# STM32H757xx register map
File version: 1.0
Registers are 32-bit, access not given, reset 0x0 unless marked. A register's access mark holds for its fields unless they carry their own. Offsets are from the block's base; [hi:lo] are bit positions; {n}, {i} and the like mark numbered series; 'fields as' and 'values as' point back to an identical list.

## DLYB_SDMMC2
Base 0x48022800
Same registers: DLYB_QUADSPI 0x52006000, DLYB_SDMMC1 0x52008000
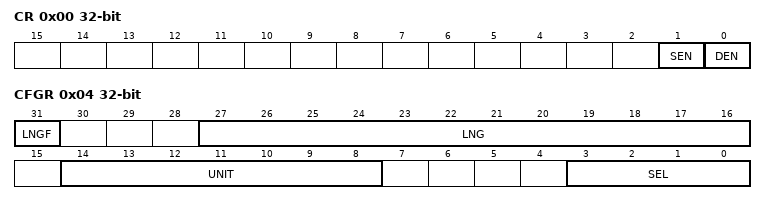
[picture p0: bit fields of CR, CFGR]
0x00 CR
  [1] SEN, [0] DEN
0x04 CFGR
  [31] LNGF, [27:16] LNG, [14:8] UNIT, [3:0] SEL

## RAMECC2
Base 0x48023000
Same registers: RAMECC1 0x52009000, RAMECC3 0x58027000
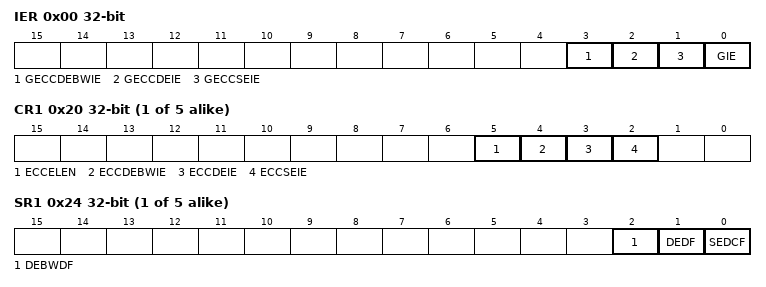
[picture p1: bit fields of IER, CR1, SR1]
0x00 IER
  [3] GECCDEBWIE, [2] GECCDEIE, [1] GECCSEIE, [0] GIE
{0x0+0x20*i} CR{i} (i=1..5)
  [5] ECCELEN, [4] ECCDEBWIE, [3] ECCDEIE, [2] ECCSEIE
{0x4+0x20*i} SR{i} (i=1..5)
  [2] DEBWDF, [1] DEDF, [0] SEDCF
{0xC+0x20*i} FAR{i} (i=1..5)
  [31:0] FDATAL
{0x18+0x20*i} FDRL{i} (i=1..5)
{0x28+0x20*i} FDRH{i} (i=1..5)
{0x3C+0x20*i} FECR{i} (i=1..5)
  [31:0] FEC

## LTDC
Base 0x50001000
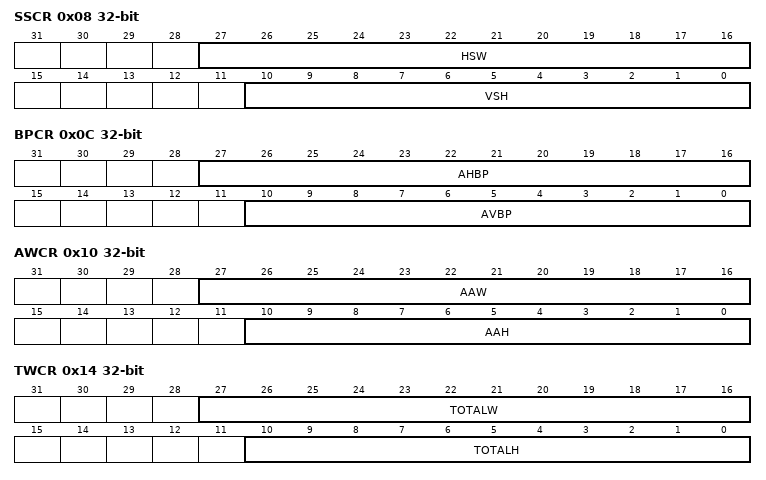
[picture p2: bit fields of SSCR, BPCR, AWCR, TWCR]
0x08 SSCR
  [27:16] HSW, [10:0] VSH
0x0C BPCR
  [27:16] AHBP, [10:0] AVBP
0x10 AWCR
  [27:16] AAW, [10:0] AAH
0x14 TWCR
  [27:16] TOTALW, [10:0] TOTALH
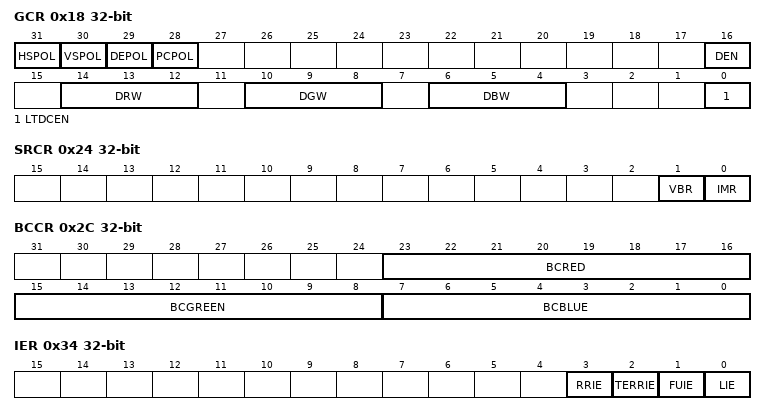
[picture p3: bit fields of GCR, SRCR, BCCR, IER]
0x18 GCR
  [31] HSPOL, [30] VSPOL, [29] DEPOL, [28] PCPOL, [16] DEN, [14:12] DRW, [10:8] DGW, [6:4] DBW, [0] LTDCEN
0x24 SRCR
  [1] VBR, [0] IMR
0x2C BCCR
  [23:16] BCRED, [15:8] BCGREEN, [7:0] BCBLUE
0x34 IER
  [3] RRIE, [2] TERRIE, [1] FUIE, [0] LIE
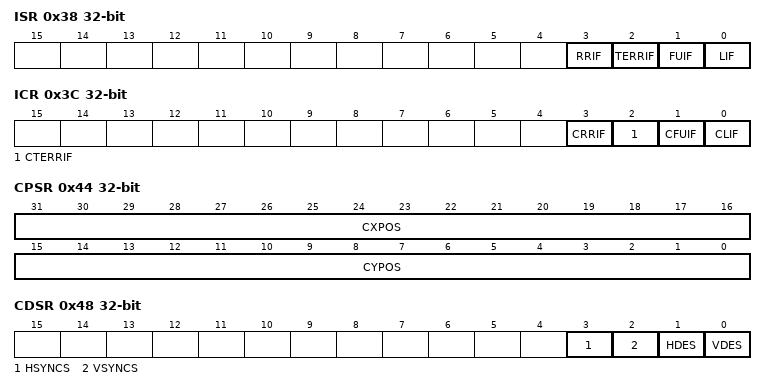
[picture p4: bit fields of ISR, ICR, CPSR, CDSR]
0x38 ISR
  [3] RRIF, [2] TERRIF, [1] FUIF, [0] LIF
0x3C ICR
  [3] CRRIF, [2] CTERRIF, [1] CFUIF, [0] CLIF
0x40 LIPCR
  [10:0] LIPOS
0x44 CPSR
  [31:16] CXPOS, [15:0] CYPOS
0x48 CDSR
  [3] HSYNCS, [2] VSYNCS, [1] HDES, [0] VDES
0x84 CR1
0x88 WHPCR1
0x90 WVPCR1
0x9C CKCR1
0xAC PFCR1
0xC0 CACR1
0xD8 DCCR1
0xF4 BFCR1
0x104 CR2
0x108 WHPCR2
0x110 WVPCR2
0x11C CFBAR1
0x11C CKCR2
0x12C PFCR2
0x140 CACR2
0x148 CFBLR1
0x158 DCCR2
0x174 BFCR2
0x178 CFBLNR1
0x19C CFBAR2
0x1B8 CLUTWR1
0x1C8 CFBLR2
0x1F8 CFBLNR2
0x238 CLUTWR2

## GPV
Base 0x51000000
{0x1FC0+4i} AXI_PERIPH_ID_{i} (i=4..7)
{0x1FE0+4i} AXI_PERIPH_ID_{i} (i=0..3)
{0x1FF0+4i} AXI_COMP_ID_{i} (i=0..3)
{0x1008+0x1000*i} AXI_TARG{i}_FN_MOD_ISS_BM (i=1..7)
0x2024 AXI_TARG1_FN_MOD2
0x202C AXI_TARG1_FN_MOD_LB
0x2108 AXI_TARG1_FN_MOD
0x3024 AXI_TARG2_FN_MOD2
0x302C AXI_TARG2_FN_MOD_LB
0x3108 AXI_TARG2_FN_MOD
0x8024 AXI_TARG7_FN_MOD2
0x802C AXI_TARG7_FN_MOD_LB
0x8108 AXI_TARG7_FN_MOD
0x42024 AXI_INI1_FN_MOD2
0x42028 AXI_INI1_FN_MOD_AHB
{0x41100+0x1000*i} AXI_INI{i}_READ_QOS (i=1..7)
{0x41104+0x1000*i} AXI_INI{i}_WRITE_QOS (i=1..7)
{0x41108+0x1000*i} AXI_INI{i}_FN_MOD (i=1..7)
0x44024 AXI_INI3_FN_MOD2
0x44028 AXI_INI3_FN_MOD_AHB

## FLASH
Base 0x52002000
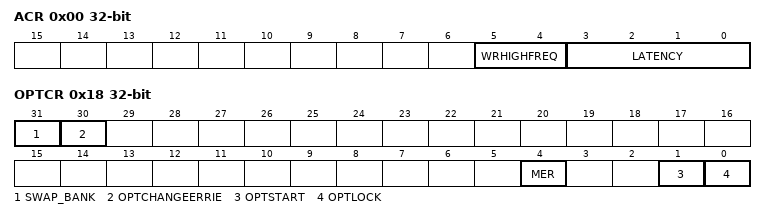
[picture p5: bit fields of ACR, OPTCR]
0x00 ACR
  [5:4] WRHIGHFREQ, [3:0] LATENCY
0x04 KEYR1
0x08 OPTKEYR
0x0C CR1
0x10 SR1
0x14 CCR1
0x18 OPTCR
  [31] SWAP_BANK, [30] OPTCHANGEERRIE, [4] MER, [1] OPTSTART, [0] OPTLOCK
0x1C OPTSR_CUR
0x20 OPTSR_PRG
0x24 OPTCCR
  [30] CLR_OPTCHANGEERR
0x28 PRAR_CUR1
0x2C PRAR_PRG1
0x30 SCAR_CUR1
0x34 SCAR_PRG1
0x38 WPSN_CUR1
0x3C WPSN_PRG1
0x40 BOOT7_CUR
0x44 BOOT7_PRG
0x48 BOOT4_CUR
0x4C BOOT4_PRG
0x50 CRCCR1
0x54 CRCSADD1
0x58 CRCEADD1
0x5C CRCDATA
  [31:0] CRC_DATA
0x60 ECC_FA1
0x104 KEYR2
0x10C CR2
0x110 SR2
0x114 CCR2
0x128 PRAR_CUR2
0x12C PRAR_PRG2
0x130 SCAR_CUR2
0x134 SCAR_PRG2
0x138 WPSN_CUR2
0x13C WPSN_PRG2
0x150 CRCCR2
0x154 CRCSADD2
0x158 CRCEADD2
0x15C CRCDATA2
0x160 ECC_FA2

## FMC_Bank1_R
Base 0x52004000
0x00 BTCR.0
0x04 BTCR.1
0x08 BTCR.2
0x0C BTCR.3
0x10 BTCR.4
0x14 BTCR.5
0x18 BTCR.6
0x1C BTCR.7

## FMC_Bank2_R
Base 0x52004060
0x00 PCR2
0x04 SR2
0x08 PMEM2
0x0C PATT2
0x14 ECCR2

## FMC_Bank3_R
Base 0x52004080
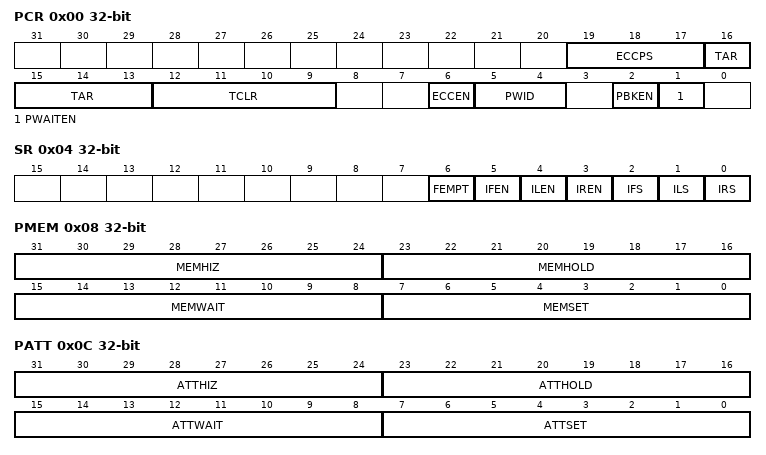
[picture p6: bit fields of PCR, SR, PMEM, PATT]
0x00 PCR
  [19:17] ECCPS, [16:13] TAR, [12:9] TCLR, [6] ECCEN, [5:4] PWID, [2] PBKEN, [1] PWAITEN
0x04 SR
  [6] FEMPT, [5] IFEN, [4] ILEN, [3] IREN, [2] IFS, [1] ILS, [0] IRS
0x08 PMEM
  [31:24] MEMHIZ, [23:16] MEMHOLD, [15:8] MEMWAIT, [7:0] MEMSET
0x0C PATT
  [31:24] ATTHIZ, [23:16] ATTHOLD, [15:8] ATTWAIT, [7:0] ATTSET
0x14 ECCR

## FMC_Bank1E_R
Base 0x52004104
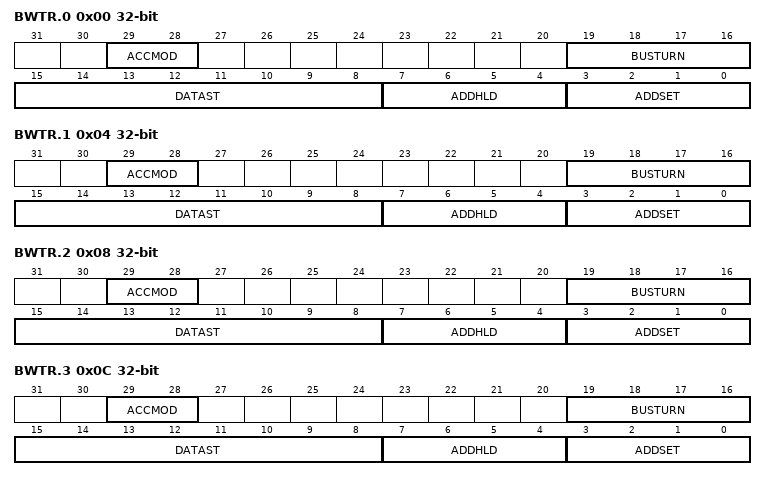
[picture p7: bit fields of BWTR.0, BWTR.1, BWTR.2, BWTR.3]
0x00 BWTR.0
  [29:28] ACCMOD, [19:16] BUSTURN, [15:8] DATAST, [7:4] ADDHLD, [3:0] ADDSET
0x04 BWTR.1
  fields as BWTR.0
0x08 BWTR.2
  fields as BWTR.0
0x0C BWTR.3
  fields as BWTR.0
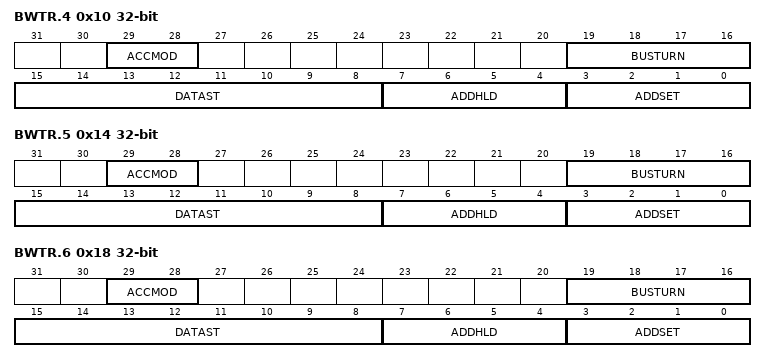
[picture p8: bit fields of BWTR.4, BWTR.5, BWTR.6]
0x10 BWTR.4
  fields as BWTR.0
0x14 BWTR.5
  fields as BWTR.0
0x18 BWTR.6
  fields as BWTR.0
